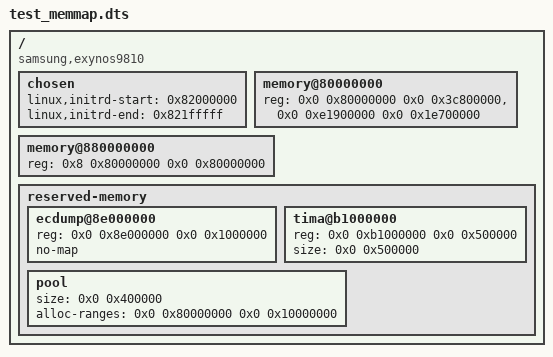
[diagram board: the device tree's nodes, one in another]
/dts-v1/;
/memreserve/ 0x80000000 0x10000;
/ {
    #address-cells = <2>;
    #size-cells = <2>;
    compatible = "samsung,exynos9810";
    chosen {
        linux,initrd-start = <0x82000000>;
        linux,initrd-end = <0x821fffff>;
    };
    memory@80000000 { device_type = "memory"; reg = <0x0 0x80000000 0x0 0x3c800000>,
                                                    <0x0 0xe1900000 0x0 0x1e700000>; };
    memory@880000000 { device_type = "memory"; reg = <0x8 0x80000000 0x0 0x80000000>; };
    reserved-memory {
        #address-cells = <2>;
        #size-cells = <2>;
        ranges;
        ecdump@8e000000 { reg = <0x0 0x8e000000 0x0 0x1000000>; no-map; };
        tima@b1000000 { reg = <0x0 0xb1000000 0x0 0x500000>; size = <0x0 0x500000>; };
        pool { size = <0x0 0x400000>; alloc-ranges = <0x0 0x80000000 0x0 0x10000000>; };
    };
};
